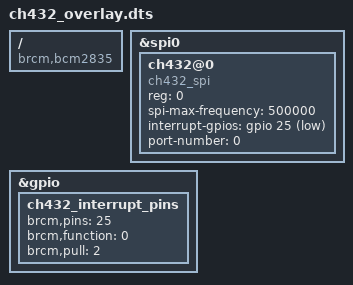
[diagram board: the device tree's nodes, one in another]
/dts-v1/;
/plugin/;

/ {
    compatible = "brcm,bcm2835";

    fragment@0 {
        target = <&spi0>;
        __overlay__ {
            #address-cells = <1>;
            #size-cells = <0>;
            status = "okay";

            ch432@0 {
                compatible = "ch432_spi";
                reg = <0>;
                spi-max-frequency = <500000>;
                interrupt-gpios = <&gpio 25 1>; //cs should be high
                port-number = <0>;
                status = "okay";
            };
        };
    };

    fragment@1 {
        target = <&gpio>;
        __overlay__ {
            ch432_interrupt_pins: ch432_interrupt_pins {
                brcm,pins = <25>;
                brcm,function = <0>; // Input
                brcm,pull = <2>;     // Pull-up
            };
        };
    };
};

/*
/dts-v1/;
/plugin/;

/ {
	fragment@0 {
		target = <&spi0>;
		__overlay__ {
			#address-cells = <1>;
			#size-cells = <0>;

			ch432@0 {
				compatible = "ch432_spi";
				reg = <0>;                         // CS0
				spi-max-frequency = <1000000>;     // 1 MHz
				interrupt-gpios = <&gpio 25 0>;
				status = "okay";
			};
		};
	};
};
*/

